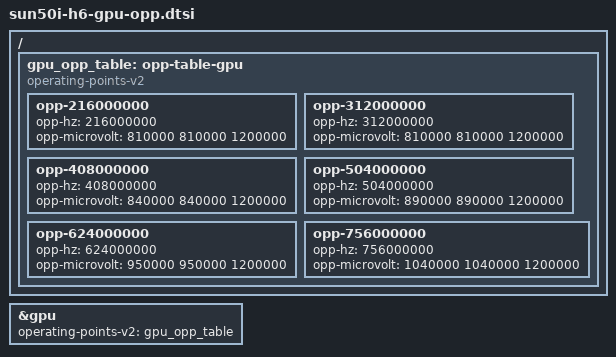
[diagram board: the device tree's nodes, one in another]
// SPDX-License-Identifier: (GPL-2.0+ OR MIT)
// Copyright (C) 2022 Clément Péron <peron.clem@gmail.com>

/ {
	gpu_opp_table: opp-table-gpu {
		compatible = "operating-points-v2";

		opp-216000000 {
			opp-hz = /bits/ 64 <216000000>;
			opp-microvolt = <810000 810000 1200000>;
		};

		opp-312000000 {
			opp-hz = /bits/ 64 <312000000>;
			opp-microvolt = <810000 810000 1200000>;
		};

		opp-408000000 {
			opp-hz = /bits/ 64 <408000000>;
			opp-microvolt = <840000 840000 1200000>;
		};

		opp-504000000 {
			opp-hz = /bits/ 64 <504000000>;
			opp-microvolt = <890000 890000 1200000>;
		};

		opp-624000000 {
			opp-hz = /bits/ 64 <624000000>;
			opp-microvolt = <950000 950000 1200000>;
		};

		opp-756000000 {
			opp-hz = /bits/ 64 <756000000>;
			opp-microvolt = <1040000 1040000 1200000>;
		};
	};
};

&gpu {
	operating-points-v2 = <&gpu_opp_table>;
};
